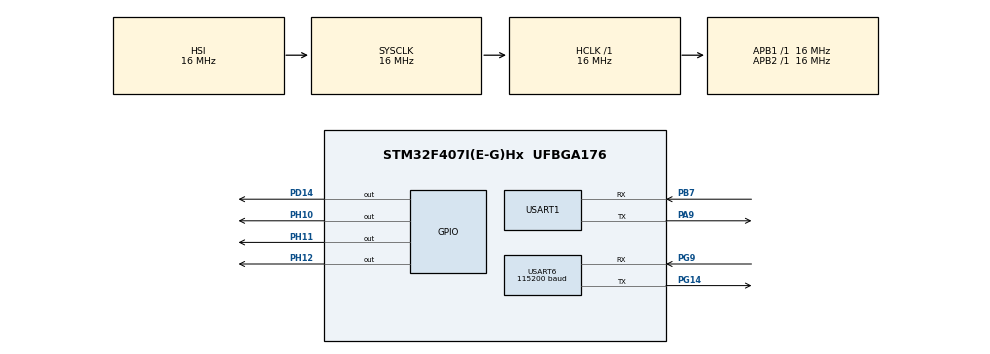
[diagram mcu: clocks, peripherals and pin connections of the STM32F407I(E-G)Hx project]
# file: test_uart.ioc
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Mcu.Family=STM32F4
Mcu.Name=STM32F407I(E-G)Hx
Mcu.Package=UFBGA176
NVIC.PriorityGroup=NVIC_PRIORITYGROUP_4
NVIC.USART6_IRQn=true\:0\:0\:false\:false\:true\:true\:true\:true
PA9.Mode=Asynchronous
PA9.Signal=USART1_TX
PB7.Mode=Asynchronous
PB7.Signal=USART1_RX
PD14.Signal=GPIO_Output
PG14.Mode=Asynchronous
PG14.Signal=USART6_TX
PG9.Mode=Asynchronous
PG9.Signal=USART6_RX
PH10.Signal=GPIO_Output
PH11.Signal=GPIO_Output
PH12.Signal=GPIO_Output
ProjectManager.HeapSize=0x200
ProjectManager.StackSize=0x400
ProjectManager.TargetToolchain=STM32CubeIDE
RCC.AHBFreq_Value=16000000
RCC.APB1Freq_Value=16000000
RCC.APB2Freq_Value=16000000
RCC.CortexFreq_Value=16000000
RCC.HSE_VALUE=25000000
RCC.HSI_VALUE=16000000
RCC.LSE_VALUE=32768
RCC.SYSCLKFreq_VALUE=16000000
RCC.VCOOutputFreq_Value=192000000
USART1.VirtualMode=VM_ASYNC
USART6.BaudRate=115200
USART6.VirtualMode=VM_ASYNC
board=custom

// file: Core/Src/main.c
/* USER CODE BEGIN Header */
/**
  ******************************************************************************
  * @file           : main.c
  * @brief          : Main program body
  ******************************************************************************
  * @attention
  *
  * Copyright (c) 2026 STMicroelectronics.
  * All rights reserved.
  *
  * This software is licensed under terms that can be found in the LICENSE file
  * in the root directory of this software component.
  * If no LICENSE file comes with this software, it is provided AS-IS.
  *
  ******************************************************************************
  */
/* USER CODE END Header */
#include "main.h"

UART_HandleTypeDef huart1;
UART_HandleTypeDef huart6;

void SystemClock_Config(void);
static void MX_GPIO_Init(void);
static void MX_USART6_UART_Init(void);
static void MX_USART1_UART_Init(void);

/* USER CODE BEGIN 0 */
char msg_buf[20];
uint8_t send_count = 0;
uint8_t rx_data[20];
HAL_StatusTypeDef send_status;
HAL_StatusTypeDef receive_status;

/* USER CODE END 0 */

int main(void)
{

  /* MCU Configuration--------------------------------------------------------*/

  /* Reset of all peripherals, Initializes the Flash interface and the Systick. */
  HAL_Init();

  /* Configure the system clock */
  SystemClock_Config();

  /* Initialize all configured peripherals */
  MX_GPIO_Init();
  MX_USART6_UART_Init();
  MX_USART1_UART_Init();

  /* Infinite loop */
  /* USER CODE BEGIN WHILE */
  while (1)
  {
//	  sprintf(msg_buf, "Hello World %03u!!\r\n", send_count);
//	  send_status = HAL_UART_Transmit(&huart6, (uint8_t*)msg_buf, 19, 100);
//	  send_count++;
//	  if (send_count > 999) send_count = 0;
//	  HAL_Delay(500);

	  receive_status = HAL_UART_Receive(&huart6, rx_data, 19, 1000);
	  HAL_Delay(499);
	  if (receive_status == HAL_OK)
	  {
		  memset(rx_data, 0, sizeof(rx_data));
	  }
	  HAL_Delay(1);
    /* USER CODE END WHILE */

  }
}

void SystemClock_Config(void)
{
  RCC_OscInitTypeDef RCC_OscInitStruct = {0};
  RCC_ClkInitTypeDef RCC_ClkInitStruct = {0};

  /** Configure the main internal regulator output voltage
  */
  __HAL_RCC_PWR_CLK_ENABLE();
  __HAL_PWR_VOLTAGESCALING_CONFIG(PWR_REGULATOR_VOLTAGE_SCALE1);

  /** Initializes the RCC Oscillators according to the specified parameters
  * in the RCC_OscInitTypeDef structure.
  */
  RCC_OscInitStruct.OscillatorType = RCC_OSCILLATORTYPE_HSI;
  RCC_OscInitStruct.HSIState = RCC_HSI_ON;
  RCC_OscInitStruct.HSICalibrationValue = RCC_HSICALIBRATION_DEFAULT;
  RCC_OscInitStruct.PLL.PLLState = RCC_PLL_NONE;
  if (HAL_RCC_OscConfig(&RCC_OscInitStruct) != HAL_OK)
  {
    Error_Handler();
  }

  /** Initializes the CPU, AHB and APB buses clocks
  */
  RCC_ClkInitStruct.ClockType = RCC_CLOCKTYPE_HCLK|RCC_CLOCKTYPE_SYSCLK
                              |RCC_CLOCKTYPE_PCLK1|RCC_CLOCKTYPE_PCLK2;
  RCC_ClkInitStruct.SYSCLKSource = RCC_SYSCLKSOURCE_HSI;
  RCC_ClkInitStruct.AHBCLKDivider = RCC_SYSCLK_DIV1;
  RCC_ClkInitStruct.APB1CLKDivider = RCC_HCLK_DIV1;
  RCC_ClkInitStruct.APB2CLKDivider = RCC_HCLK_DIV1;

  if (HAL_RCC_ClockConfig(&RCC_ClkInitStruct, FLASH_LATENCY_0) != HAL_OK)
  {
    Error_Handler();
  }
}

static void MX_USART1_UART_Init(void)
{

  huart1.Instance = USART1;
  huart1.Init.BaudRate = 115200;
  huart1.Init.WordLength = UART_WORDLENGTH_8B;
  huart1.Init.StopBits = UART_STOPBITS_1;
  huart1.Init.Parity = UART_PARITY_NONE;
  huart1.Init.Mode = UART_MODE_TX_RX;
  huart1.Init.HwFlowCtl = UART_HWCONTROL_NONE;
  huart1.Init.OverSampling = UART_OVERSAMPLING_16;
  if (HAL_UART_Init(&huart1) != HAL_OK)
  {
    Error_Handler();
  }

}

static void MX_USART6_UART_Init(void)
{

  huart6.Instance = USART6;
  huart6.Init.BaudRate = 115200;
  huart6.Init.WordLength = UART_WORDLENGTH_8B;
  huart6.Init.StopBits = UART_STOPBITS_1;
  huart6.Init.Parity = UART_PARITY_NONE;
  huart6.Init.Mode = UART_MODE_TX_RX;
  huart6.Init.HwFlowCtl = UART_HWCONTROL_NONE;
  huart6.Init.OverSampling = UART_OVERSAMPLING_16;
  if (HAL_UART_Init(&huart6) != HAL_OK)
  {
    Error_Handler();
  }

}

static void MX_GPIO_Init(void)
{
  GPIO_InitTypeDef GPIO_InitStruct = {0};

  /* GPIO Ports Clock Enable */
  __HAL_RCC_GPIOG_CLK_ENABLE();
  __HAL_RCC_GPIOB_CLK_ENABLE();
  __HAL_RCC_GPIOA_CLK_ENABLE();
  __HAL_RCC_GPIOH_CLK_ENABLE();
  __HAL_RCC_GPIOD_CLK_ENABLE();

  /*Configure GPIO pin Output Level */
  HAL_GPIO_WritePin(GPIOH, GPIO_PIN_12|GPIO_PIN_11|GPIO_PIN_10, GPIO_PIN_RESET);

  /*Configure GPIO pin Output Level */
  HAL_GPIO_WritePin(GPIOD, GPIO_PIN_14, GPIO_PIN_RESET);

  /*Configure GPIO pins : PH12 PH11 PH10 */
  GPIO_InitStruct.Pin = GPIO_PIN_12|GPIO_PIN_11|GPIO_PIN_10;
  GPIO_InitStruct.Mode = GPIO_MODE_OUTPUT_PP;
  GPIO_InitStruct.Pull = GPIO_NOPULL;
  GPIO_InitStruct.Speed = GPIO_SPEED_FREQ_LOW;
  HAL_GPIO_Init(GPIOH, &GPIO_InitStruct);

  /*Configure GPIO pin : PD14 */
  GPIO_InitStruct.Pin = GPIO_PIN_14;
  GPIO_InitStruct.Mode = GPIO_MODE_OUTPUT_PP;
  GPIO_InitStruct.Pull = GPIO_NOPULL;
  GPIO_InitStruct.Speed = GPIO_SPEED_FREQ_LOW;
  HAL_GPIO_Init(GPIOD, &GPIO_InitStruct);

}

void Error_Handler(void)
{
  __disable_irq();
  while (1)
  {
  }
}
